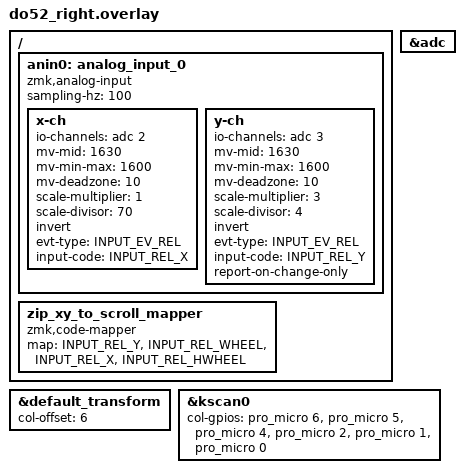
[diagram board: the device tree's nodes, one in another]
#include "do52.dtsi"
#include <zephyr/dt-bindings/input/input-event-codes.h>
/* Reference: https://docs.zephyrproject.org/apidoc/latest/group__input__events.html */

&adc {
	status = "okay";
};

/ {
	anin0: analog_input_0 {
		compatible = "zmk,analog-input";
		sampling-hz = <100>;
		x-ch {
			io-channels = <&adc 2>;
			mv-mid = <1630>;
			mv-min-max = <1600>;
			mv-deadzone = <10>;
			scale-multiplier = <1>;
			scale-divisor = <70>;
			invert;
			evt-type = <INPUT_EV_REL>;
			input-code = <INPUT_REL_X>;
		};
		y-ch {
			io-channels = <&adc 3>;
			mv-mid = <1630>;
			mv-min-max = <1600>;
			mv-deadzone = <10>;
			scale-multiplier = <3>;
			scale-divisor = <4>;
			invert;
			evt-type = <INPUT_EV_REL>;
			input-code = <INPUT_REL_Y>;

			/* enable report mdoe for gamepad axix or knob */
			/* to only call input_report on quantquantized value is updated */
			report-on-change-only;

		};
	};
    zip_xy_to_scroll_mapper: zip_xy_to_scroll_mapper {
        compatible = "zmk,code-mapper";
        map = <INPUT_REL_Y>, <INPUT_REL_WHEEL>,
              <INPUT_REL_X>, <INPUT_REL_HWHEEL>;
    };
};

&default_transform { 
    col-offset = <6>;
};

&kscan0 {
    col-gpios
        = <&pro_micro 6 GPIO_ACTIVE_HIGH>
        , <&pro_micro 5 GPIO_ACTIVE_HIGH>
        , <&pro_micro 4 GPIO_ACTIVE_HIGH>
        , <&pro_micro 2 GPIO_ACTIVE_HIGH>
        , <&pro_micro 1 GPIO_ACTIVE_HIGH>
        , <&pro_micro 0 GPIO_ACTIVE_HIGH>
        ;
};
